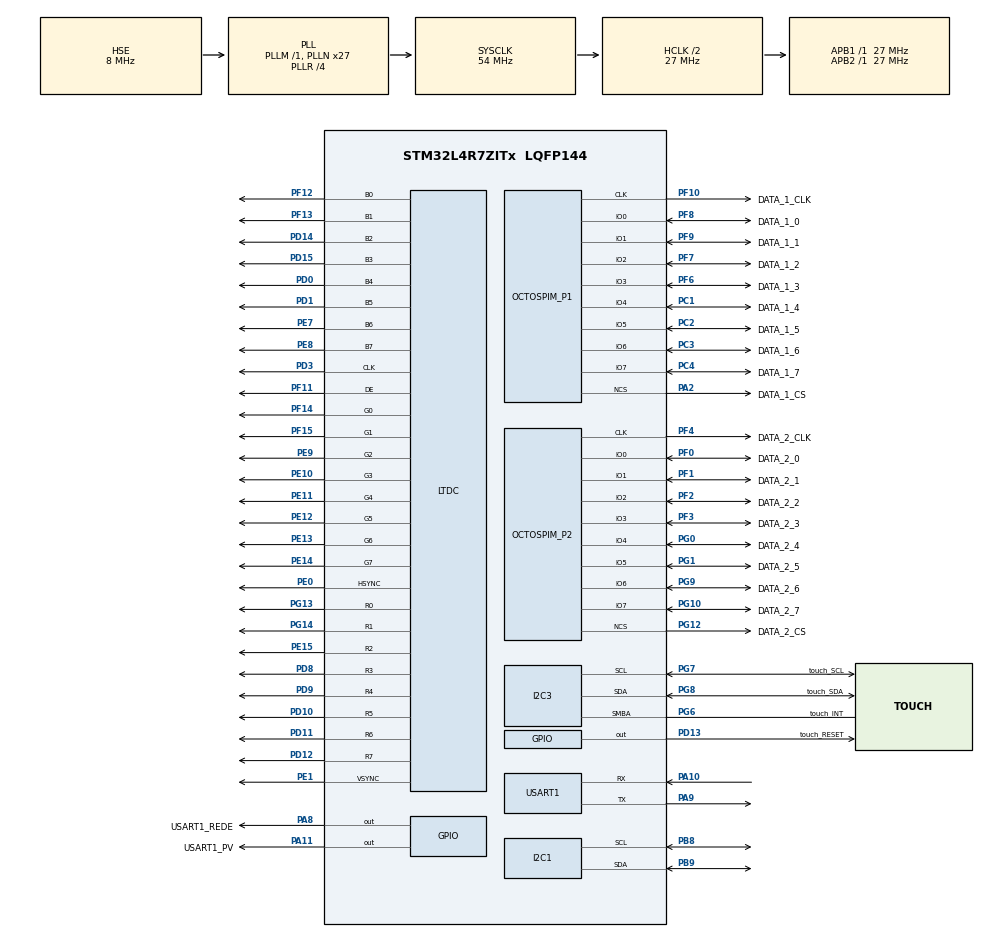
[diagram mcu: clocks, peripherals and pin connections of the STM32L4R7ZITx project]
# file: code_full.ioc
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GFXMMU.BlocksPerLine=GFXMMU_256BLOCKS
GFXMMU.Buf0Address=0x0
GFXMMU.Buf1Address=0x0000ffff
GFXMMU.Buf2Address=0x0
GFXMMU.Buf3Address=0x0000ffff
GFXMMU.GFXMMU_AHB_MASTER_ERROR_IT=Enable
GFXMMU.GFXMMU_BUFFER0_OVERFLOW_IT=Enable
GFXMMU.GFXMMU_BUFFER1_OVERFLOW_IT=Enable
GFXMMU.GFXMMU_BUFFER2_OVERFLOW_IT=Enable
GFXMMU.GFXMMU_BUFFER3_OVERFLOW_IT=Enable
I2C1.Timing=0x00906997
I2C3.Timeout=0x00008149
I2C3.Timing=0x00906997
LTDC.Alpha_L0=255
LTDC.Alpha_L1=255
LTDC.Blue_L0=255
LTDC.Layers=0
LTDC.WindowX1_L0=800
LTDC.WindowX1_L1=640
LTDC.WindowY1_L0=600
LTDC.WindowY1_L1=480
Mcu.Family=STM32L4
Mcu.Name=STM32L4R7ZITx
Mcu.Package=LQFP144
NVIC.FPU_IRQn=true\:0\:0\:false\:false\:true\:true\:false\:true
NVIC.GFXMMU_IRQn=true\:0\:0\:false\:false\:true\:true\:true\:true
NVIC.I2C1_ER_IRQn=true\:0\:0\:false\:false\:true\:true\:true\:true
NVIC.I2C1_EV_IRQn=true\:0\:0\:false\:false\:true\:true\:true\:true
NVIC.I2C3_ER_IRQn=true\:0\:0\:false\:false\:true\:true\:true\:true
NVIC.I2C3_EV_IRQn=true\:0\:0\:false\:false\:true\:true\:true\:true
NVIC.LTDC_ER_IRQn=true\:0\:0\:false\:false\:true\:true\:true\:true
NVIC.LTDC_IRQn=true\:0\:0\:false\:false\:true\:true\:true\:true
NVIC.OCTOSPI1_IRQn=true\:0\:0\:false\:false\:true\:true\:true\:true
NVIC.OCTOSPI2_IRQn=true\:0\:0\:false\:false\:true\:true\:true\:true
NVIC.PriorityGroup=NVIC_PRIORITYGROUP_4
NVIC.TIM1_UP_TIM16_IRQn=true\:15\:0\:false\:false\:true\:true\:true\:true
NVIC.TIM2_IRQn=true\:0\:0\:false\:false\:true\:true\:true\:true
NVIC.TIM3_IRQn=true\:0\:0\:false\:false\:true\:true\:true\:true
NVIC.TimeBase=TIM1_UP_TIM16_IRQn
NVIC.TimeBaseIP=TIM1
PA0.Mode=SYS_WakeUp0
PA0.Signal=SYS_WKUP1
PA10.Mode=Asynchronous
PA10.Signal=USART1_RX
PA11.GPIO_Label=USART1_PV
PA11.Signal=GPIO_Output
PA13\ (JTMS/SWDIO).Mode=JTAG_5_pins
PA13\ (JTMS/SWDIO).Signal=SYS_JTMS-SWDIO
PA14\ (JTCK/SWCLK).Mode=JTAG_5_pins
PA14\ (JTCK/SWCLK).Signal=SYS_JTCK-SWCLK
PA15\ (JTDI).Mode=JTAG_5_pins
PA15\ (JTDI).Signal=SYS_JTDI
PA2.GPIO_Label=DATA_1_CS
PA2.Mode=OCTOSPI1_Port1_NCS
PA2.Signal=OCTOSPIM_P1_NCS
PA8.GPIO_Label=USART1_REDE
PA8.Signal=GPIO_Output
PA9.Mode=Asynchronous
PA9.Signal=USART1_TX
PB3\ (JTDO/TRACESWO).Mode=JTAG_5_pins
PB3\ (JTDO/TRACESWO).Signal=SYS_JTDO-SWO
PB4\ (NJTRST).Mode=JTAG_5_pins
PB4\ (NJTRST).Signal=SYS_JTRST
PB7.Mode=Mode_PVD_Ext
PB7.Signal=SYS_PVD_IN
PB8.Mode=I2C
PB8.Signal=I2C1_SCL
PB9.Mode=I2C
PB9.Signal=I2C1_SDA
PC1.GPIO_Label=DATA_1_4
PC1.Mode=OCTOSPI1_IOH_Port1H
PC1.Signal=OCTOSPIM_P1_IO4
PC2.GPIO_Label=DATA_1_5
PC2.Mode=OCTOSPI1_IOH_Port1H
PC2.Signal=OCTOSPIM_P1_IO5
PC3.GPIO_Label=DATA_1_6
PC3.Mode=OCTOSPI1_IOH_Port1H
PC3.Signal=OCTOSPIM_P1_IO6
PC4.GPIO_Label=DATA_1_7
PC4.Mode=OCTOSPI1_IOH_Port1H
PC4.Signal=OCTOSPIM_P1_IO7
PD0.Mode=RGB888
PD0.Signal=LTDC_B4
PD1.Mode=RGB888
PD1.Signal=LTDC_B5
PD10.Mode=RGB888
PD10.Signal=LTDC_R5
PD11.Mode=RGB888
PD11.Signal=LTDC_R6
PD12.Mode=RGB888
PD12.Signal=LTDC_R7
PD13.GPIO_Label=touch_RESET
PD13.Signal=GPIO_Output
PD14.Mode=RGB888
PD14.Signal=LTDC_B2
PD15.Mode=RGB888
PD15.Signal=LTDC_B3
PD3.Mode=RGB888
PD3.Signal=LTDC_CLK
PD8.Mode=RGB888
PD8.Signal=LTDC_R3
PD9.Mode=RGB888
PD9.Signal=LTDC_R4
PE0.Mode=RGB888
PE0.Signal=LTDC_HSYNC
PE1.Mode=RGB888
PE1.Signal=LTDC_VSYNC
PE10.Mode=RGB888
PE10.Signal=LTDC_G3
PE11.Mode=RGB888
PE11.Signal=LTDC_G4
PE12.Mode=RGB888
PE12.Signal=LTDC_G5
PE13.Mode=RGB888
PE13.Signal=LTDC_G6
PE14.Mode=RGB888
PE14.Signal=LTDC_G7
PE15.Mode=RGB888
PE15.Signal=LTDC_R2
PE7.Mode=RGB888
PE7.Signal=LTDC_B6
PE8.Mode=RGB888
PE8.Signal=LTDC_B7
PE9.Mode=RGB888
PE9.Signal=LTDC_G2
PF0.GPIO_Label=DATA_2_0
PF0.Mode=OCTOSPI2_IOL_Port2L
PF0.Signal=OCTOSPIM_P2_IO0
PF1.GPIO_Label=DATA_2_1
PF1.Mode=OCTOSPI2_IOL_Port2L
PF1.Signal=OCTOSPIM_P2_IO1
PF10.GPIO_Label=DATA_1_CLK
PF10.Mode=O1_P1_CLK
PF10.Signal=OCTOSPIM_P1_CLK
PF11.Mode=RGB888
PF11.Signal=LTDC_DE
PF12.Mode=RGB888
PF12.Signal=LTDC_B0
PF13.Mode=RGB888
PF13.Signal=LTDC_B1
PF14.Mode=RGB888
PF14.Signal=LTDC_G0
PF15.Mode=RGB888
PF15.Signal=LTDC_G1
PF2.GPIO_Label=DATA_2_2
PF2.Mode=OCTOSPI2_IOL_Port2L
PF2.Signal=OCTOSPIM_P2_IO2
PF3.GPIO_Label=DATA_2_3
PF3.Mode=OCTOSPI2_IOL_Port2L
PF3.Signal=OCTOSPIM_P2_IO3
PF4.GPIO_Label=DATA_2_CLK
PF4.Mode=O2_P2_CLK
PF4.Signal=OCTOSPIM_P2_CLK
PF6.GPIO_Label=DATA_1_3
PF6.Mode=OCTOSPI1_IOL_Port1L
PF6.Signal=OCTOSPIM_P1_IO3
PF7.GPIO_Label=DATA_1_2
PF7.Mode=OCTOSPI1_IOL_Port1L
PF7.Signal=OCTOSPIM_P1_IO2
PF8.GPIO_Label=DATA_1_0
PF8.Mode=OCTOSPI1_IOL_Port1L
PF8.Signal=OCTOSPIM_P1_IO0
PF9.GPIO_Label=DATA_1_1
PF9.Mode=OCTOSPI1_IOL_Port1L
PF9.Signal=OCTOSPIM_P1_IO1
PG0.GPIO_Label=DATA_2_4
PG0.Mode=OCTOSPI2_IOH_Port2H
PG0.Signal=OCTOSPIM_P2_IO4
PG1.GPIO_Label=DATA_2_5
PG1.Mode=OCTOSPI2_IOH_Port2H
PG1.Signal=OCTOSPIM_P2_IO5
PG10.GPIO_Label=DATA_2_7
PG10.Mode=OCTOSPI2_IOH_Port2H
PG10.Signal=OCTOSPIM_P2_IO7
PG12.GPIO_Label=DATA_2_CS
PG12.Mode=OCTOSPI2_Port2_NCS
PG12.Signal=OCTOSPIM_P2_NCS
PG13.Mode=RGB888
PG13.Signal=LTDC_R0
PG14.Mode=RGB888
PG14.Signal=LTDC_R1
PG6.GPIO_Label=touch_INT
PG6.Mode=SMBus-Alert-mode
PG6.Signal=I2C3_SMBA
PG7.GPIO_Label=touch_SCL
PG7.Mode=SMBus-Alert-mode
PG7.Signal=I2C3_SCL
PG8.GPIO_Label=touch_SDA
PG8.Mode=SMBus-Alert-mode
PG8.Signal=I2C3_SDA
PG9.GPIO_Label=DATA_2_6
PG9.Mode=OCTOSPI2_IOH_Port2H
PG9.Signal=OCTOSPIM_P2_IO6
PH0-OSC_IN\ (PH0).Mode=HSE-External-Oscillator
PH0-OSC_IN\ (PH0).Signal=RCC_OSC_IN
PH1-OSC_OUT\ (PH1).Mode=HSE-External-Oscillator
PH1-OSC_OUT\ (PH1).Signal=RCC_OSC_OUT
ProjectManager.HeapSize=0x200
ProjectManager.StackSize=0x400
ProjectManager.TargetToolchain=MDK-ARM V5.32
RCC.ADCFreq_Value=32000000
RCC.AHBCLKDivider=RCC_SYSCLK_DIV2
RCC.AHBFreq_Value=27000000
RCC.APB1Freq_Value=27000000
RCC.APB1TimFreq_Value=27000000
RCC.APB2Freq_Value=27000000
RCC.APB2TimFreq_Value=27000000
RCC.CortexFreq_Value=27000000
RCC.EnbaleCSS=true
RCC.HCLKFreq_Value=27000000
RCC.HSE_VALUE=8000000
RCC.HSI48_VALUE=48000000
RCC.HSI_VALUE=16000000
RCC.LSE_VALUE=32768
RCC.MSI_VALUE=4000000
RCC.PLLN=27
RCC.PLLR=RCC_PLLR_DIV4
RCC.PLLSAI2N=27
RCC.PLLSAI2R=RCC_PLLR_DIV4
RCC.PLLSourceVirtual=RCC_PLLSOURCE_HSE
RCC.SYSCLKFreq_VALUE=54000000
RCC.SYSCLKSource=RCC_SYSCLKSOURCE_PLLCLK
RCC.USART1CLockSelection=RCC_USART1CLKSOURCE_HSI
RCC.USBFreq_Value=32000000
RCC.VCOOutputFreq_Value=216000000
STMicroelectronics.X-CUBE-TOUCHGFX.4.25.0.ApplicationCcGraphicsJjApplication=TouchGFXOoGenerator
STMicroelectronics.X-CUBE-TOUCHGFX.4.25.0.tgfx_buffering_strategy=Partial-LTDC
STMicroelectronics.X-CUBE-TOUCHGFX.4.25.0.tgfx_display_interface=disp_ltdc
STMicroelectronics.X-CUBE-TOUCHGFX.4.25.0.tgfx_hardware_accelerator=dma_2d
STMicroelectronics.X-CUBE-TOUCHGFX.4.25.0.tgfx_location=Allocate
STMicroelectronics.X-CUBE-TOUCHGFX.4.25.0.tgfx_oswrapper=CMSIS V2
STMicroelectronics.X-CUBE-TOUCHGFX.4.25.0.tgfx_pixel_format=ARGB8888\:32
STMicroelectronics.X-CUBE-TOUCHGFX.4.25.0.tgfx_vector_fonts=Enabled
STMicroelectronics.X-CUBE-TOUCHGFX.4.25.0.tgfx_vector_rendering=Software
STMicroelectronics.X-CUBE-TOUCHGFX.4.25.0.tgfx_vsync=vsync_ltdc
STMicroelectronics.X-CUBE-TOUCHGFX.4.25.0_IsPackSelfContextualization=true
USART1.VirtualMode-Asynchronous=VM_ASYNC
VP_CRC_VS_CRC.Mode=CRC_Activate
VP_DMA2D_VS_DMA2D.Mode=DMA2D_Activate
VP_GFXMMU_VS_GFXMMU.Mode=GFXMMU_Activate
VP_OCTOSPI1_VS_octo.Mode=dual_quad_mode
VP_OCTOSPI2_VS_octo.Mode=dual_quad_mode_mx
VP_STMicroelectronics.X-CUBE-TOUCHGFX_VS_GraphicsJjApplication_4.25.0.Mode=GraphicsJjApplication
VP_SYS_VS_DBSignals.Mode=DisableDeadBatterySignals
VP_SYS_VS_LPOM.Mode=PowerOptimisation
VP_SYS_VS_tim1.Mode=TIM1
VP_TIM2_VS_ClockSourceINT.Mode=Internal
VP_TIM3_VS_ClockSourceINT.Mode=Internal
VP_WWDG_VS_WWDG.Mode=WWDG_Activate
board=custom

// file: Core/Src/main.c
/* USER CODE BEGIN Header */
/**
  ******************************************************************************
  * @file           : main.c
  * @brief          : Main program body
  ******************************************************************************
  * @attention
  *
  * Copyright (c) 2025 STMicroelectronics.
  * All rights reserved.
  *
  * This software is licensed under terms that can be found in the LICENSE file
  * in the root directory of this software component.
  * If no LICENSE file comes with this software, it is provided AS-IS.
  *
  ******************************************************************************
  */
/* USER CODE END Header */
#include "main.h"
#include "gfxmmu_lut.h"
#include "crc.h"
#include "dma2d.h"
#include "gfxmmu.h"
#include "i2c.h"
#include "ltdc.h"
#include "octospi.h"
#include "tim.h"
#include "usart.h"
#include "wwdg.h"
#include "gpio.h"
#include "app_touchgfx.h"

/* USER CODE BEGIN Includes */
#include "string.h"
#include "stdio.h"
/* USER CODE END Includes */

void SystemClock_Config(void);

int main(void)
{

  /* MCU Configuration--------------------------------------------------------*/

  /* Reset of all peripherals, Initializes the Flash interface and the Systick. */
  HAL_Init();

  /* Configure the system clock */
  SystemClock_Config();

  /* Initialize all configured peripherals */
  MX_GPIO_Init();
  MX_I2C1_Init();
  MX_I2C3_SMBUS_Init();
  MX_LTDC_Init();
  MX_USART1_UART_Init();
  MX_OCTOSPI1_Init();
  MX_OCTOSPI2_Init();
  MX_TIM2_Init();
  MX_TIM3_Init();
  MX_GFXMMU_Init();
  MX_CRC_Init();
  MX_DMA2D_Init();
  MX_WWDG_Init();
  MX_TouchGFX_Init();

  /* Infinite loop */
  while (1)
  {

  MX_TouchGFX_Process();
  }
}

void SystemClock_Config(void)
{
  RCC_OscInitTypeDef RCC_OscInitStruct = {0};
  RCC_ClkInitTypeDef RCC_ClkInitStruct = {0};

  /** Configure the main internal regulator output voltage
  */
  if (HAL_PWREx_ControlVoltageScaling(PWR_REGULATOR_VOLTAGE_SCALE1) != HAL_OK)
  {
    Error_Handler();
  }

  /** Initializes the RCC Oscillators according to the specified parameters
  * in the RCC_OscInitTypeDef structure.
  */
  RCC_OscInitStruct.OscillatorType = RCC_OSCILLATORTYPE_HSI|RCC_OSCILLATORTYPE_HSE;
  RCC_OscInitStruct.HSEState = RCC_HSE_ON;
  RCC_OscInitStruct.HSIState = RCC_HSI_ON;
  RCC_OscInitStruct.HSICalibrationValue = RCC_HSICALIBRATION_DEFAULT;
  RCC_OscInitStruct.PLL.PLLState = RCC_PLL_ON;
  RCC_OscInitStruct.PLL.PLLSource = RCC_PLLSOURCE_HSE;
  RCC_OscInitStruct.PLL.PLLM = 1;
  RCC_OscInitStruct.PLL.PLLN = 27;
  RCC_OscInitStruct.PLL.PLLP = RCC_PLLP_DIV2;
  RCC_OscInitStruct.PLL.PLLQ = RCC_PLLQ_DIV2;
  RCC_OscInitStruct.PLL.PLLR = RCC_PLLR_DIV4;
  if (HAL_RCC_OscConfig(&RCC_OscInitStruct) != HAL_OK)
  {
    Error_Handler();
  }

  /** Initializes the CPU, AHB and APB buses clocks
  */
  RCC_ClkInitStruct.ClockType = RCC_CLOCKTYPE_HCLK|RCC_CLOCKTYPE_SYSCLK
                              |RCC_CLOCKTYPE_PCLK1|RCC_CLOCKTYPE_PCLK2;
  RCC_ClkInitStruct.SYSCLKSource = RCC_SYSCLKSOURCE_PLLCLK;
  RCC_ClkInitStruct.AHBCLKDivider = RCC_SYSCLK_DIV2;
  RCC_ClkInitStruct.APB1CLKDivider = RCC_HCLK_DIV1;
  RCC_ClkInitStruct.APB2CLKDivider = RCC_HCLK_DIV1;

  if (HAL_RCC_ClockConfig(&RCC_ClkInitStruct, FLASH_LATENCY_1) != HAL_OK)
  {
    Error_Handler();
  }

  /** Enables the Clock Security System
  */
  HAL_RCC_EnableCSS();
}

void HAL_TIM_PeriodElapsedCallback(TIM_HandleTypeDef *htim)
{
  if (htim->Instance == TIM1) {
    HAL_IncTick();
  }
}

void Error_Handler(void)
{
  __disable_irq();
  while (1)
  {
  }
}
